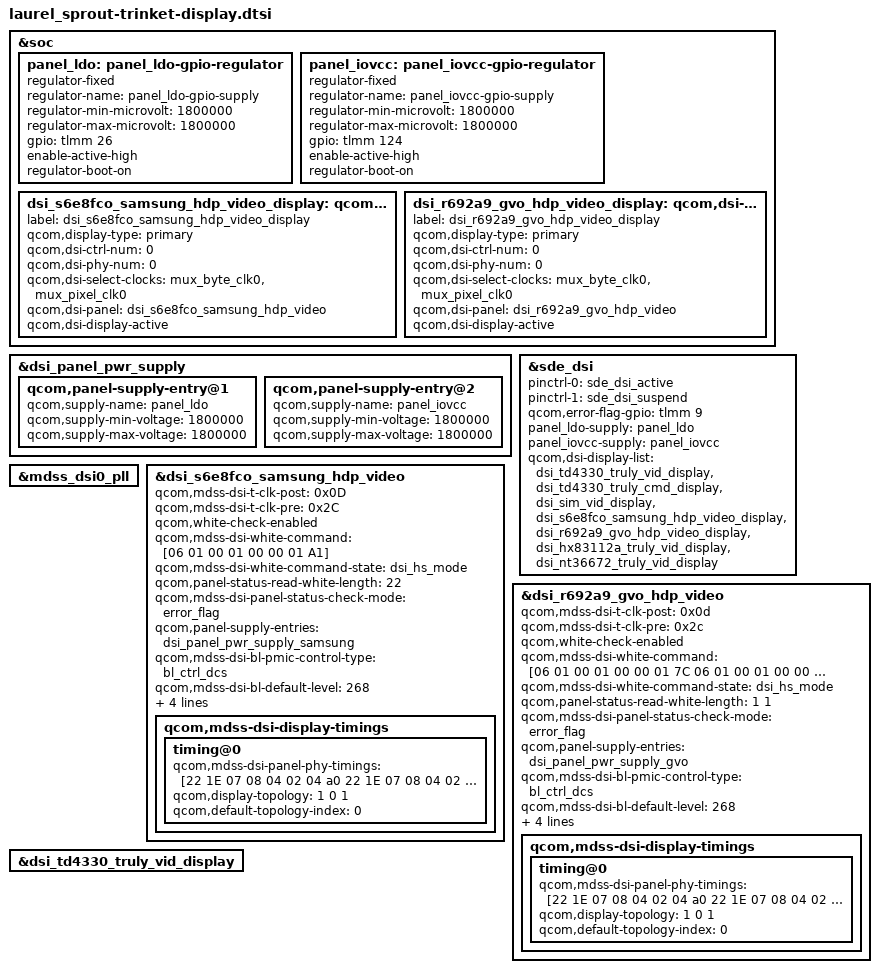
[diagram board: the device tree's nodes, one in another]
#include "display/dsi-panel-s6e8fco-samsung-amoled-hdp-video.dtsi"
#include "display/dsi-panel-r692a9-gvo-amoled-hdp-video.dtsi"

&soc {
    panel_ldo: panel_ldo-gpio-regulator {
        compatible = "regulator-fixed";

        regulator-name = "panel_ldo-gpio-supply";
        regulator-min-microvolt = <1800000>;
        regulator-max-microvolt = <1800000>;

        gpio = <&tlmm 26 0>;
        enable-active-high;
        regulator-boot-on;
    };

    panel_iovcc: panel_iovcc-gpio-regulator {
        compatible = "regulator-fixed";

        regulator-name = "panel_iovcc-gpio-supply";
        regulator-min-microvolt = <1800000>;
        regulator-max-microvolt = <1800000>;

        gpio = <&tlmm 124 0>;
        enable-active-high;
        regulator-boot-on;
    };

    dsi_s6e8fco_samsung_hdp_video_display: qcom,dsi-display@5 {
        label = "dsi_s6e8fco_samsung_hdp_video_display";
        qcom,display-type = "primary";

        qcom,dsi-ctrl-num = <0>;
        qcom,dsi-phy-num = <0>;
        qcom,dsi-select-clocks = "mux_byte_clk0", "mux_pixel_clk0";

        qcom,dsi-panel = <&dsi_s6e8fco_samsung_hdp_video>;
    };

    dsi_r692a9_gvo_hdp_video_display: qcom,dsi-display@6 {
        label = "dsi_r692a9_gvo_hdp_video_display";
        qcom,display-type = "primary";

        qcom,dsi-ctrl-num = <0>;
        qcom,dsi-phy-num = <0>;
        qcom,dsi-select-clocks = "mux_byte_clk0", "mux_pixel_clk0";

        qcom,dsi-panel = <&dsi_r692a9_gvo_hdp_video>;
    };
};

&dsi_panel_pwr_supply {
    qcom,panel-supply-entry@1 {
        qcom,supply-name = "panel_ldo";
        qcom,supply-min-voltage = <1800000>;
        qcom,supply-max-voltage = <1800000>;
    };

    qcom,panel-supply-entry@2 {
        qcom,supply-name = "panel_iovcc";
        qcom,supply-min-voltage = <1800000>;
        qcom,supply-max-voltage = <1800000>;
        /delete-property/ qcom,supply-post-on-sleep;
    };
};

&sde_dsi {
    pinctrl-0 = <&sde_dsi_active>;
    pinctrl-1 = <&sde_dsi_suspend>;
    qcom,error-flag-gpio = <&tlmm 9 0>;
    /delete-property/ qcom,platform-te-gpio;

    /delete-property/ lab-supply;
    /delete-property/ ibb-supply;
    panel_ldo-supply = <&panel_ldo>;
    panel_iovcc-supply = <&panel_iovcc>;

    qcom,dsi-display-list =
        <&dsi_td4330_truly_vid_display
        &dsi_td4330_truly_cmd_display
        &dsi_sim_vid_display
        &dsi_s6e8fco_samsung_hdp_video_display
        &dsi_r692a9_gvo_hdp_video_display
        &dsi_hx83112a_truly_vid_display
        &dsi_nt36672_truly_vid_display>;
};

&mdss_dsi0_pll {
    /delete-property/ qcom,dsi-pll-ssc-en;
};

&dsi_s6e8fco_samsung_hdp_video {
    qcom,mdss-dsi-t-clk-post = <0x0D>;
    qcom,mdss-dsi-t-clk-pre = <0x2C>;
    qcom,white-check-enabled;
    qcom,mdss-dsi-white-command = [06 01 00 01 00 00 01 A1];
    qcom,mdss-dsi-white-command-state = "dsi_hs_mode";
    qcom,panel-status-read-white-length = <22>;

    qcom,mdss-dsi-panel-status-check-mode = "error_flag";

    qcom,mdss-dsi-display-timings {
        timing@0{
            qcom,mdss-dsi-panel-phy-timings =
                [22 1E 07 08 04 02 04 a0
                22 1E 07 08 04 02 04 a0
                22 1E 07 08 04 02 04 a0
                22 1E 07 08 04 02 04 a0
                22 18 07 08 04 02 04 a0];

            qcom,display-topology = <1 0 1>;
            qcom,default-topology-index = <0>;
        };
    };
};

&dsi_r692a9_gvo_hdp_video {
    qcom,mdss-dsi-t-clk-post = <0x0d>;
    qcom,mdss-dsi-t-clk-pre = <0x2c>;
    qcom,white-check-enabled;
    qcom,mdss-dsi-white-command = [06 01 00 01 00 00 01 7C
        06 01 00 01 00 00 01 7D];
    qcom,mdss-dsi-white-command-state = "dsi_hs_mode";
    qcom,panel-status-read-white-length = <1 1>;

    qcom,mdss-dsi-panel-status-check-mode = "error_flag";

    qcom,mdss-dsi-display-timings {
        timing@0{
            qcom,mdss-dsi-panel-phy-timings =
                [22 1E 07 08 04 02 04 a0
                22 1E 07 08 04 02 04 a0
                22 1E 07 08 04 02 04 a0
                22 1E 07 08 04 02 04 a0
                22 18 07 08 04 02 04 a0];

            qcom,display-topology = <1 0 1>;
            qcom,default-topology-index = <0>;
        };
    };
};

&dsi_s6e8fco_samsung_hdp_video {
    qcom,panel-supply-entries = <&dsi_panel_pwr_supply_samsung>;
    qcom,mdss-dsi-bl-pmic-control-type = "bl_ctrl_dcs";
    qcom,mdss-dsi-bl-default-level = <268>;
    qcom,mdss-dsi-bl-min-level = <4>;
    qcom,mdss-dsi-bl-max-level = <2047>;
    qcom,mdss-brightness-max-level = <2047>;
    qcom,platform-reset-gpio = <&tlmm 90 0>;
};

&dsi_s6e8fco_samsung_hdp_video_display {
    qcom,dsi-display-active;
};

&dsi_r692a9_gvo_hdp_video {
    qcom,panel-supply-entries = <&dsi_panel_pwr_supply_gvo>;
    qcom,mdss-dsi-bl-pmic-control-type = "bl_ctrl_dcs";
    qcom,mdss-dsi-bl-default-level = <268>;
    qcom,mdss-dsi-bl-min-level = <4>;
    qcom,mdss-dsi-bl-max-level = <4095>;
    qcom,mdss-brightness-max-level = <2047>;
    qcom,platform-reset-gpio = <&tlmm 90 0>;
};

&dsi_r692a9_gvo_hdp_video_display {
    qcom,dsi-display-active;
};

&dsi_td4330_truly_vid_display {
    /delete-property/ qcom,dsi-display-active;
};
